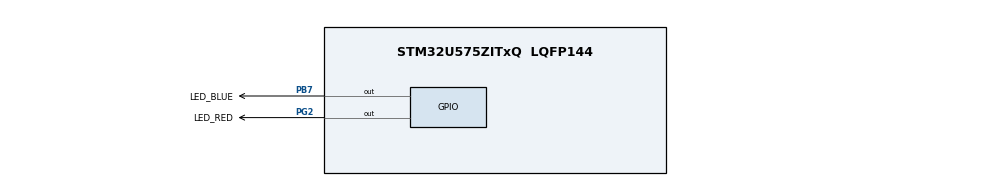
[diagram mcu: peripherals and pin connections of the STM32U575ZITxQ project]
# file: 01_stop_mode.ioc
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CORTEX_M33_NS.userName=CORTEX_M33
Mcu.Family=STM32U5
Mcu.Name=STM32U575ZITxQ
Mcu.Package=LQFP144
NVIC.PriorityGroup=NVIC_PRIORITYGROUP_4
NVIC.RTC_IRQn=true\:0\:0\:false\:false\:true\:true\:true\:true
PA13\ (JTMS/SWDIO).Mode=Trace_Asynchronous_SW
PA13\ (JTMS/SWDIO).Signal=DEBUG_JTMS-SWDIO
PA14\ (JTCK/SWCLK).Mode=Trace_Asynchronous_SW
PA14\ (JTCK/SWCLK).Signal=DEBUG_JTCK-SWCLK
PB3\ (JTDO/TRACESWO).Mode=Trace_Asynchronous_SW
PB3\ (JTDO/TRACESWO).Signal=DEBUG_JTDO-SWO
PB7.GPIO_Label=LED_BLUE
PB7.Signal=GPIO_Output
PC14-OSC32_IN\ (PC14).Mode=LSE-External-Oscillator
PC14-OSC32_IN\ (PC14).Signal=RCC_OSC32_IN
PC15-OSC32_OUT\ (PC15).Mode=LSE-External-Oscillator
PC15-OSC32_OUT\ (PC15).Signal=RCC_OSC32_OUT
PG2.GPIO_Label=LED_RED
PG2.Signal=GPIO_Output
PWR.PowerMode=PWR_SMPS_SUPPLY
ProjectManager.HeapSize=0x200
ProjectManager.StackSize=0x400
ProjectManager.TargetToolchain=STM32CubeIDE
RCC.ADCFreq_Value=16000000
RCC.EPOD_VALUE=4000000
RCC.HSE_VALUE=16000000
RCC.HSI48_VALUE=48000000
RCC.HSI_VALUE=16000000
RCC.LSIDIV_VALUE=32000
RCC.MSI_VALUE=4000000
RCC.RTCClockSelection=RCC_RTCCLKSOURCE_LSE
RCC.USBFreq_Value=48000000
RCC.VCOOutputFreq_Value=516000000
RTC.WakeUpClock-WakeUp=RTC_WAKEUPCLOCK_RTCCLK_DIV16
RTC.WakeUpCounter-WakeUp=16384
VP_ICACHE_VS_ICACHE.Mode=DirectMappedCache
VP_PWR_VS_DBSignals.Mode=DisableDeadBatterySignals
VP_PWR_VS_LPOM.Mode=PowerOptimisation
VP_RTC_VS_RTC_Activate.Mode=RTC_Enabled
VP_RTC_VS_RTC_WakeUp_intern.Mode=WakeUp
board=custom

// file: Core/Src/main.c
/* USER CODE BEGIN Header */
/**
  ******************************************************************************
  * @file           : main.c
  * @brief          : Main program body
  ******************************************************************************
  * @attention
  *
  * Autor: dhs (Daniel H Sagarra)
  *
  * Measures:
  * 1) Stop mode 2 current consumption 7.8 uA
  *
  *
  * Tricks a tips:
  *
  * 1) Some When using RTC in Stop0/1/2 we must enable RTC autonomous mode by:
  *    __HAL_RCC_RTCAPB_CLKAM_ENABLE();
  *
  * 2) In stop mode 2 and deeper systick clock will be halted, in others low
  * power modes systick keeps running and interrups will wake up STM32, so to
  * not abort low power mode following code will be needed:
  * HAL_SuspendTick();
  * ... // go to low power mode code.
  * HAL_ResumeTick();
  *
  ******************************************************************************
  */
/* USER CODE END Header */
#include "main.h"

/* USER CODE BEGIN PD */

/*
 *  dhs: calculate wake up counter to get a wake up interrupt every n seconds.
 */
#define DHS_RTC_FREQUENCY 32768
#define DHS_RTC_DIVIDER   16
#define DHS_RTC_SECONDS   4
#define DHS_RTC_WAKEUP_COUNTER (( DHS_RTC_FREQUENCY / DHS_RTC_DIVIDER) * DHS_RTC_SECONDS)

/*
 *  Miliseconds in active mode
 */
#define DHS_MILISECONDS_IN_ACTIVE_MODE 10

/* USER CODE END PD */

RTC_HandleTypeDef hrtc;

void SystemClock_Config(void);
static void SystemPower_Config(void);
static void MX_GPIO_Init(void);
static void MX_ICACHE_Init(void);
static void MX_RTC_Init(void);

int main(void)
{

  /* MCU Configuration--------------------------------------------------------*/

  /* Reset of all peripherals, Initializes the Flash interface and the Systick. */
  HAL_Init();

  /* Configure the system clock */
  SystemClock_Config();

  /* Configure the System Power */
  SystemPower_Config();

  /* Initialize all configured peripherals */
  MX_GPIO_Init();
  MX_ICACHE_Init();
  MX_RTC_Init();

  /* Infinite loop */
  /* USER CODE BEGIN WHILE */
  while (1)
  {

    HAL_SuspendTick();
    HAL_PWREx_EnterSTOP2Mode(PWR_STOPENTRY_WFI);
    HAL_ResumeTick();

    HAL_GPIO_WritePin(LED_BLUE_GPIO_Port, LED_BLUE_Pin, GPIO_PIN_SET);
    HAL_Delay(DHS_MILISECONDS_IN_ACTIVE_MODE);
    HAL_GPIO_WritePin(LED_BLUE_GPIO_Port, LED_BLUE_Pin, GPIO_PIN_RESET);

    /* USER CODE END WHILE */

  }
}

void SystemClock_Config(void)
{
  RCC_OscInitTypeDef RCC_OscInitStruct = {0};
  RCC_ClkInitTypeDef RCC_ClkInitStruct = {0};

  /** Configure the main internal regulator output voltage
  */
  if (HAL_PWREx_ControlVoltageScaling(PWR_REGULATOR_VOLTAGE_SCALE4) != HAL_OK)
  {
    Error_Handler();
  }

  /** Configure LSE Drive Capability
  */
  HAL_PWR_EnableBkUpAccess();
  __HAL_RCC_LSEDRIVE_CONFIG(RCC_LSEDRIVE_LOW);

  /** Initializes the CPU, AHB and APB buses clocks
  */
  RCC_OscInitStruct.OscillatorType = RCC_OSCILLATORTYPE_LSE|RCC_OSCILLATORTYPE_MSI;
  RCC_OscInitStruct.LSEState = RCC_LSE_ON;
  RCC_OscInitStruct.MSIState = RCC_MSI_ON;
  RCC_OscInitStruct.MSICalibrationValue = RCC_MSICALIBRATION_DEFAULT;
  RCC_OscInitStruct.MSIClockRange = RCC_MSIRANGE_4;
  RCC_OscInitStruct.PLL.PLLState = RCC_PLL_NONE;
  if (HAL_RCC_OscConfig(&RCC_OscInitStruct) != HAL_OK)
  {
    Error_Handler();
  }

  /** Initializes the CPU, AHB and APB buses clocks
  */
  RCC_ClkInitStruct.ClockType = RCC_CLOCKTYPE_HCLK|RCC_CLOCKTYPE_SYSCLK
                              |RCC_CLOCKTYPE_PCLK1|RCC_CLOCKTYPE_PCLK2
                              |RCC_CLOCKTYPE_PCLK3;
  RCC_ClkInitStruct.SYSCLKSource = RCC_SYSCLKSOURCE_MSI;
  RCC_ClkInitStruct.AHBCLKDivider = RCC_SYSCLK_DIV1;
  RCC_ClkInitStruct.APB1CLKDivider = RCC_HCLK_DIV1;
  RCC_ClkInitStruct.APB2CLKDivider = RCC_HCLK_DIV1;
  RCC_ClkInitStruct.APB3CLKDivider = RCC_HCLK_DIV1;

  if (HAL_RCC_ClockConfig(&RCC_ClkInitStruct, FLASH_LATENCY_0) != HAL_OK)
  {
    Error_Handler();
  }
}

/**
  * @brief Power Configuration
  * @retval None
  */
static void SystemPower_Config(void)
{
  HAL_PWREx_EnableVddIO2();

  /*
   * Disable the internal Pull-Up in Dead Battery pins of UCPD peripheral
   */
  HAL_PWREx_DisableUCPDDeadBattery();

  /*
   * Switch to SMPS regulator instead of LDO
   */
  if (HAL_PWREx_ConfigSupply(PWR_SMPS_SUPPLY) != HAL_OK)
  {
    Error_Handler();
  }
}

static void MX_ICACHE_Init(void)
{

  /** Enable instruction cache in 1-way (direct mapped cache)
  */
  if (HAL_ICACHE_ConfigAssociativityMode(ICACHE_1WAY) != HAL_OK)
  {
    Error_Handler();
  }
  if (HAL_ICACHE_Enable() != HAL_OK)
  {
    Error_Handler();
  }

}

static void MX_RTC_Init(void)
{

  RTC_PrivilegeStateTypeDef privilegeState = {0};

  /** Initialize RTC Only
  */
  hrtc.Instance = RTC;
  hrtc.Init.HourFormat = RTC_HOURFORMAT_24;
  hrtc.Init.AsynchPrediv = 127;
  hrtc.Init.SynchPrediv = 255;
  hrtc.Init.OutPut = RTC_OUTPUT_DISABLE;
  hrtc.Init.OutPutRemap = RTC_OUTPUT_REMAP_NONE;
  hrtc.Init.OutPutPolarity = RTC_OUTPUT_POLARITY_HIGH;
  hrtc.Init.OutPutType = RTC_OUTPUT_TYPE_OPENDRAIN;
  hrtc.Init.OutPutPullUp = RTC_OUTPUT_PULLUP_NONE;
  hrtc.Init.BinMode = RTC_BINARY_NONE;
  if (HAL_RTC_Init(&hrtc) != HAL_OK)
  {
    Error_Handler();
  }
  privilegeState.rtcPrivilegeFull = RTC_PRIVILEGE_FULL_NO;
  privilegeState.backupRegisterPrivZone = RTC_PRIVILEGE_BKUP_ZONE_NONE;
  privilegeState.backupRegisterStartZone2 = RTC_BKP_DR0;
  privilegeState.backupRegisterStartZone3 = RTC_BKP_DR0;
  if (HAL_RTCEx_PrivilegeModeSet(&hrtc, &privilegeState) != HAL_OK)
  {
    Error_Handler();
  }

  /** Enable the WakeUp
  */
  if (HAL_RTCEx_SetWakeUpTimer_IT(&hrtc, 16384, RTC_WAKEUPCLOCK_RTCCLK_DIV16, 0) != HAL_OK)
  {
    Error_Handler();
  }
  /* USER CODE BEGIN RTC_Init 2 */

  /*
   * dhs: program wakeup with custom values.
   */
  if (HAL_RTCEx_SetWakeUpTimer_IT(&hrtc, DHS_RTC_WAKEUP_COUNTER, RTC_WAKEUPCLOCK_RTCCLK_DIV16, 0) != HAL_OK)
    {
      Error_Handler();
    }

  /*
   * dhs: enable the autonomous mode for the RTC in Stop0/1/2
   */
    __HAL_RCC_RTCAPB_CLKAM_ENABLE();

  /* USER CODE END RTC_Init 2 */

}

static void MX_GPIO_Init(void)
{
  GPIO_InitTypeDef GPIO_InitStruct = {0};

  /* GPIO Ports Clock Enable */
  __HAL_RCC_GPIOC_CLK_ENABLE();
  __HAL_RCC_GPIOG_CLK_ENABLE();
  __HAL_RCC_GPIOA_CLK_ENABLE();
  __HAL_RCC_GPIOB_CLK_ENABLE();

  /*Configure GPIO pin Output Level */
  HAL_GPIO_WritePin(LED_RED_GPIO_Port, LED_RED_Pin, GPIO_PIN_RESET);

  /*Configure GPIO pin Output Level */
  HAL_GPIO_WritePin(LED_BLUE_GPIO_Port, LED_BLUE_Pin, GPIO_PIN_RESET);

  /*Configure GPIO pin : LED_RED_Pin */
  GPIO_InitStruct.Pin = LED_RED_Pin;
  GPIO_InitStruct.Mode = GPIO_MODE_OUTPUT_PP;
  GPIO_InitStruct.Pull = GPIO_NOPULL;
  GPIO_InitStruct.Speed = GPIO_SPEED_FREQ_LOW;
  HAL_GPIO_Init(LED_RED_GPIO_Port, &GPIO_InitStruct);

  /*Configure GPIO pin : LED_BLUE_Pin */
  GPIO_InitStruct.Pin = LED_BLUE_Pin;
  GPIO_InitStruct.Mode = GPIO_MODE_OUTPUT_PP;
  GPIO_InitStruct.Pull = GPIO_NOPULL;
  GPIO_InitStruct.Speed = GPIO_SPEED_FREQ_LOW;
  HAL_GPIO_Init(LED_BLUE_GPIO_Port, &GPIO_InitStruct);

}

/* USER CODE BEGIN 4 */

/*
 * dhs: periodic wake up interrupt, custom isr.
 */
void HAL_RTCEx_WakeUpTimerEventCallback(RTC_HandleTypeDef *hrtc)
{
  /*
   * @dhs: only wake up the STM32, no extra code needed.
   */

}

/* USER CODE END 4 */

void Error_Handler(void)
{
  /* USER CODE BEGIN Error_Handler_Debug */
  /* User can add his own implementation to report the HAL error return state */
  __disable_irq();

  /*
   * dhs: red LED turns on whenever a error is detected.
   */
  HAL_GPIO_WritePin(LED_RED_GPIO_Port, LED_RED_Pin, GPIO_PIN_SET);
  while (1)
  {

  }
  /* USER CODE END Error_Handler_Debug */
}
